# STM32F0x0 register map
File version: 1.2
CPU: CM0 r0p0, little endian, no MPU, no FPU, 2 interrupt priority bits
Registers are 32-bit, read-write, reset 0x0 unless marked. A register's access mark holds for its fields unless they carry their own. Offsets are from the block's base; [hi:lo] are bit positions; {n}, {i} and the like mark numbered series; 'fields as' and 'values as' point back to an identical list.

## SYSCFG — System configuration controller
Base 0x40010000
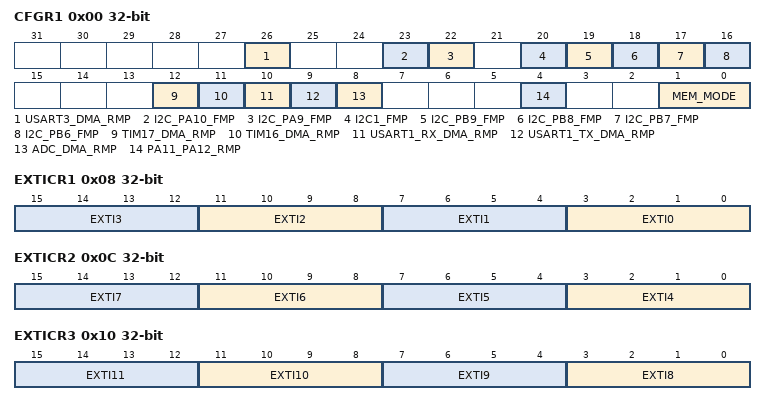
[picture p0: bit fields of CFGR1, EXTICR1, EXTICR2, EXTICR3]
0x00 CFGR1 — configuration register 1
  [26] USART3_DMA_RMP — USART3 DMA request remapping bit
    0=NotRemapped (USART3_RX and USART3_TX DMA requests mapped on DMA channel 6 and 7 respectively (or simply disabled on STM32F0x0)); 1=Remapped (USART3_RX and USART3_TX DMA requests mapped on DMA channel 3 and 2 respectively)
  [23] I2C_PA10_FMP — Fast Mode Plus (FM+) driving capability activation bits
    0=Standard (PA10 pin operate in standard mode); 1=FMP (I2C FM+ mode enabled on PA10 and the Speed control is bypassed)
  [22] I2C_PA9_FMP — Fast Mode Plus (FM+) driving capability activation bits
    0=Standard (PA9 pin operate in standard mode); 1=FMP (I2C FM+ mode enabled on PA9 and the Speed control is bypassed)
  [20] I2C1_FMP — FM+ driving capability activation for I2C1
    0=Standard (FM+ mode is controlled by I2C_Pxx_FMP bits only); 1=FMP (FM+ mode is enabled on all I2C1 pins selected through selection bits in GPIOx_AFR registers)
  [19] I2C_PB9_FMP — Fast Mode Plus (FM+) driving capability activation bits.
    0=Standard (PB9 pin operate in standard mode); 1=FMP (I2C FM+ mode enabled on PB9 and the Speed control is bypassed)
  [18] I2C_PB8_FMP — Fast Mode Plus (FM+) driving capability activation bits.
    0=Standard (PB8 pin operate in standard mode); 1=FMP (I2C FM+ mode enabled on PB8 and the Speed control is bypassed)
  [17] I2C_PB7_FMP — Fast Mode Plus (FM+) driving capability activation bits.
    0=Standard (PB7 pin operate in standard mode); 1=FMP (I2C FM+ mode enabled on PB7 and the Speed control is bypassed)
  [16] I2C_PB6_FMP — Fast Mode Plus (FM plus) driving capability activation bits.
    0=Standard (PB6 pin operate in standard mode); 1=FMP (I2C FM+ mode enabled on PB6 and the Speed control is bypassed)
  [12] TIM17_DMA_RMP — TIM17 DMA request remapping bit
    0=NotRemapped (TIM17_CH1 and TIM17_UP DMA request mapped on DMA channel 1); 1=Remapped (TIM17_CH1 and TIM17_UP DMA request mapped on DMA channel 2)
  [11] TIM16_DMA_RMP — TIM16 DMA request remapping bit
    0=NotRemapped (TIM16_CH1 and TIM16_UP DMA request mapped on DMA channel 3); 1=Remapped (TIM16_CH1 and TIM16_UP DMA request mapped on DMA channel 4)
  [10] USART1_RX_DMA_RMP — USART1_RX DMA request remapping bit
    0=NotRemapped (USART1_RX DMA request mapped on DMA channel 3); 1=Remapped (USART1_RX DMA request mapped on DMA channel 5)
  [9] USART1_TX_DMA_RMP — USART1_TX DMA remapping bit
    0=NotRemapped (USART1_TX DMA request mapped on DMA channel 2); 1=Remapped (USART1_TX DMA request mapped on DMA channel 4)
  [8] ADC_DMA_RMP — ADC DMA remapping bit
    0=NotRemapped (ADC DMA request mapped on DMA channel 1); 1=Remapped (ADC DMA request mapped on DMA channel 2)
  [4] PA11_PA12_RMP — PA11 and PA12 remapping bit for small packages (28 and 20 pins)
    0=NotRemapped (Pin pair PA9/PA10 mapped on the pins); 1=Remapped (Pin pair PA11/PA12 mapped instead of PA9/PA10)
  [1:0] MEM_MODE — Memory mapping selection bits
    0=Main Flash memory mapped at 0x0000_0000; 1=System Flash memory mapped at 0x0000_0000; 2=MainFlash2 (Main Flash memory mapped at 0x0000_0000); 3=SRAM (Embedded SRAM mapped at 0x0000_0000)
0x08 EXTICR1 — external interrupt configuration register 1
  [all] fields
    0=PA (Select PAx as the source input for the EXTIx external interrupt); 1=PB (Select PBx as the source input for the EXTIx external interrupt); 2=PC (Select PCx as the source input for the EXTIx external interrupt); 3=PD (Select PDx as the source input for the EXTIx external interrupt); 5=PF (Select PFx as the source input for the EXTIx external interrupt)
  [4n+3:4n] EXTI{n} (n=0..3) — EXTI {n} configuration bits
0x0C EXTICR2 — external interrupt configuration register 2
  [all] fields
    values as the fields of EXTICR1
  [4n-13:4n-16] EXTI{n} (n=4..7) — EXTI {n} configuration bits
0x10 EXTICR3 — external interrupt configuration register 3
  [all] fields
    values as the fields of EXTICR1
  [4n-29:4n-32] EXTI{n} (n=8..11) — EXTI {n} configuration bits
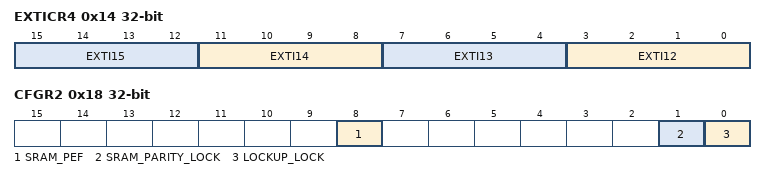
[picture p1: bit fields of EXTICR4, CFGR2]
0x14 EXTICR4 — external interrupt configuration register 4
  [all] fields
    values as the fields of EXTICR1
  [4n-45:4n-48] EXTI{n} (n=12..15) — EXTI {n} configuration bits
0x18 CFGR2 — configuration register 2
  [8] SRAM_PEF — SRAM parity flag
    on read: 0=NoParityError (No SRAM parity error detected); 1=ParityErrorDetected (SRAM parity error detected) | on write: 1=Clear SRAM parity error flag
  [1] SRAM_PARITY_LOCK — SRAM parity lock bit
    0=Disconnected (SRAM parity error disconnected from TIM1/15/16/17 Break input); 1=Connected (SRAM parity error connected to TIM1/15/16/17 Break input)
  [0] LOCKUP_LOCK — Cortex-M0 LOCKUP bit enable bit
    0=Disconnected (Cortex-M0 LOCKUP output disconnected from TIM1/15/16/17 Break input); 1=Connected (Cortex-M0 LOCKUP output connected to TIM1/15/16/17 Break input)
